# LPC55S28 register map
Vendor: nxp.com; File version: 1.0
CPU: CM33 r2p0, little endian, MPU, FPU, VTOR, 3 interrupt priority bits
Registers are 32-bit, read-write, reset 0x0 unless marked. A register's access mark holds for its fields unless they carry their own. Offsets are from the block's base; [hi:lo] are bit positions; {n}, {i} and the like mark numbered series.

## OSTIMER — Synchronous OS/Event timer with Wakeup Timer
Base 0x4002D000
0x00 EVTIMERL ro — EVTIMER Low Register
  [31:0] EVTIMER_COUNT_VALUE — A read reflects the current value of the lower 32 bits of the 42-bits EVTIMER. Note: There is only one EVTIMER, readable from all domains.
0x04 EVTIMERH — EVTIMER High Register
  [9:0] EVTIMER_COUNT_VALUE ro — A read reflects the current value of the upper 10 bits of the 42-bits EVTIMER. Note there is only one EVTIMER, readable from all domains.
0x08 CAPTURE_L ro — Capture Low Register
  [31:0] CAPTURE_VALUE — A read reflects the value of the lower 32 bits of the central 42-bits EVTIMER at the time the last capture signal was generated by the CPU (using CMSIS C function "__SEV();").
0x0C CAPTURE_H — Capture High Register
  [9:0] CAPTURE_VALUE ro — A read reflects the value of the upper 10 bits of the central 42-bits EVTIMER at the time the last capture signal was generated by the CPU (using CMSIS C function "__SEV();").
0x10 MATCH_L — Match Low Register
  [31:0] MATCH_VALUE — The value written to the MATCH (L/H) register pair is compared against the central EVTIMER. When a match occurs, an interrupt request is generated if enabled.
0x14 MATCH_H — Match High Register
  [9:0] MATCH_VALUE — The value written (upper 10 bits) to the MATCH (L/H) register pair is compared against the central EVTIMER. When a match occurs, an interrupt request is generated if enabled.
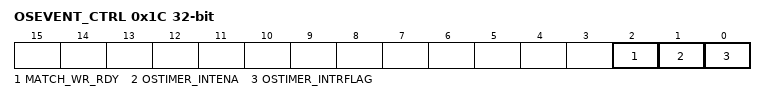
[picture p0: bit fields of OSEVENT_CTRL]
0x1C OSEVENT_CTRL — OS_EVENT TIMER Control Register
  [2] MATCH_WR_RDY ro — This bit will be low when it is safe to write to reload the Match Registers. In typical applications it should not be necessary to test this bit. [1]
  [1] OSTIMER_INTENA — When this bit is '1' an interrupt/wakeup request to the domain processor will be asserted when the OSTIMER_INTR flag is set. When this bit is '0', interrupt/wakeup requests due to the OSTIMER_INTR flag are blocked.
  [0] OSTIMER_INTRFLAG — This bit is set when a match occurs between the central 42-bits EVTIMER and the value programmed in the match-register pair. This bit is cleared by writing a '1'. Writes to clear this bit are asynchronous. It should be done before a new match value is written into the MATCH_L/H registers.

## PRINCE
Base 0x40035000
0x00 ENC_ENABLE — Encryption Enable register
  [0] EN — Encryption Enable.
    0=DISABLED (Encryption of writes to the flash controller DATAW* registers is disabled.); 1=ENABLED (Encryption of writes to the flash controller DATAW* registers is enabled.)
0x04 MASK_LSB wo — Data Mask register, 32 Least Significant Bits
  [31:0] MASKVAL — Value of the 32 Least Significant Bits of the 64-bit data mask.
0x08 MASK_MSB wo — Data Mask register, 32 Most Significant Bits
  [31:0] MASKVAL — Value of the 32 Most Significant Bits of the 64-bit data mask.
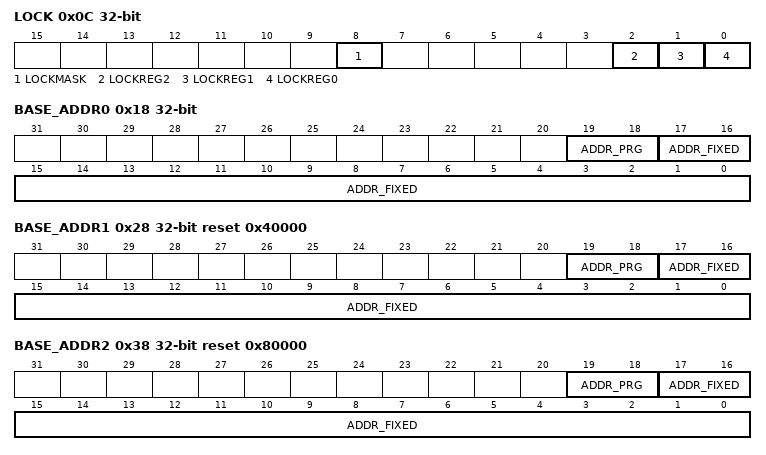
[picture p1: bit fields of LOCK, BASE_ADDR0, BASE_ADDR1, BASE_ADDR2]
0x0C LOCK
  [8] LOCKMASK — Lock the Mask registers.
    0=DISABLED (Disabled. MASK_LSB, and MASK_MSB are writable..); 1=ENABLED (Enabled. MASK_LSB, and MASK_MSB are not writable..)
  [2] LOCKREG2 — Lock Region 2 registers.
    0=DISABLED (Disabled. IV_LSB2, IV_MSB2, BASE_ADDR2, and SR_ENABLE2 are writable..); 1=ENABLED (Enabled. IV_LSB2, IV_MSB2, BASE_ADDR2, and SR_ENABLE2 are not writable..)
  [1] LOCKREG1 — Lock Region 1 registers.
    0=DISABLED (Disabled. IV_LSB1, IV_MSB1, BASE_ADDR1, and SR_ENABLE1 are writable..); 1=ENABLED (Enabled. IV_LSB1, IV_MSB1, BASE_ADDR1, and SR_ENABLE1 are not writable..)
  [0] LOCKREG0 — Lock Region 0 registers.
    0=DISABLED (Disabled. IV_LSB0, IV_MSB0, BASE_ADDR0, and SR_ENABLE0 are writable..); 1=ENABLED (Enabled. IV_LSB0, IV_MSB0, BASE_ADDR0, and SR_ENABLE0 are not writable..)
{0x10+0x10*i} IV_LSB{i} wo (i=0..2) — Initial Vector register for region {i}, Least Significant Bits
  [31:0] IVVAL — Initial Vector value for the 32 Least Significant Bits of the 64-bit Initial Vector.
{0x14+0x10*i} IV_MSB{i} wo (i=0..2) — Initial Vector register for region {i}, Most Significant Bits
  [31:0] IVVAL — Initial Vector value for the 32 Most Significant Bits of the 64-bit Initial Vector.
0x18 BASE_ADDR0 — Base Address for region 0 register
  [19:18] ADDR_PRG — Programmable portion of the base address of region 0.
  [17:0] ADDR_FIXED ro — Fixed portion of the base address of region 0.
{0x1C+0x10*i} SR_ENABLE{i} (i=0..2) — Sub-Region Enable register for region {i}
  [31:0] EN — Each bit in this field enables an 8KB subregion for encryption at offset 8KB*bitnum of region {i}.
0x28 BASE_ADDR1 reset 0x40000 — Base Address for region 1 register
  [19:18] ADDR_PRG — Programmable portion of the base address of region 1.
  [17:0] ADDR_FIXED ro — Fixed portion of the base address of region 1.
0x38 BASE_ADDR2 reset 0x80000 — Base Address for region 2 register
  [19:18] ADDR_PRG — Programmable portion of the base address of region 2.
  [17:0] ADDR_FIXED ro — Fixed portion of the base address of region 2.

## Notices in the file
Copyright 2016-2020 NXP
All rights reserved.
SPDX-License-Identifier: BSD-3-Clause
